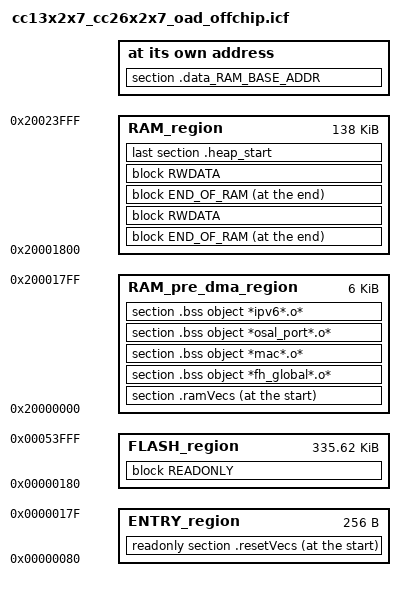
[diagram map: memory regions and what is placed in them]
/******************************************************************************

 @file  cc13x2x7_cc26x2x7_oad_offchip.icf

 @brief Linker configuration file

 Group: WCS LPC
 Target Device: cc13xx_cc26xx

 ******************************************************************************
 
 Copyright (c) 2016-2025, Texas Instruments Incorporated
 All rights reserved.

 Redistribution and use in source and binary forms, with or without
 modification, are permitted provided that the following conditions
 are met:

 *  Redistributions of source code must retain the above copyright
    notice, this list of conditions and the following disclaimer.

 *  Redistributions in binary form must reproduce the above copyright
    notice, this list of conditions and the following disclaimer in the
    documentation and/or other materials provided with the distribution.

 *  Neither the name of Texas Instruments Incorporated nor the names of
    its contributors may be used to endorse or promote products derived
    from this software without specific prior written permission.

 THIS SOFTWARE IS PROVIDED BY THE COPYRIGHT HOLDERS AND CONTRIBUTORS "AS IS"
 AND ANY EXPRESS OR IMPLIED WARRANTIES, INCLUDING, BUT NOT LIMITED TO,
 THE IMPLIED WARRANTIES OF MERCHANTABILITY AND FITNESS FOR A PARTICULAR
 PURPOSE ARE DISCLAIMED. IN NO EVENT SHALL THE COPYRIGHT OWNER OR
 CONTRIBUTORS BE LIABLE FOR ANY DIRECT, INDIRECT, INCIDENTAL, SPECIAL,
 EXEMPLARY, OR CONSEQUENTIAL DAMAGES (INCLUDING, BUT NOT LIMITED TO,
 PROCUREMENT OF SUBSTITUTE GOODS OR SERVICES; LOSS OF USE, DATA, OR PROFITS;
 OR BUSINESS INTERRUPTION) HOWEVER CAUSED AND ON ANY THEORY OF LIABILITY,
 WHETHER IN CONTRACT, STRICT LIABILITY, OR TORT (INCLUDING NEGLIGENCE OR
 OTHERWISE) ARISING IN ANY WAY OUT OF THE USE OF THIS SOFTWARE,
 EVEN IF ADVISED OF THE POSSIBILITY OF SUCH DAMAGE.

 ******************************************************************************
 
 
 *****************************************************************************/

///////////////////////////////////////////////////////////////////////////////
// Memory Sizes
///////////////////////////////////////////////////////////////////////////////
define symbol MCUBOOT_HEAD_SIZE    = 0x80;
define symbol ENTRY_SIZE           = 0x100;
define symbol MCUBOOT_RESERVED_TRAILER_SIZE = 0x2000;

define symbol PRIMARY_SLOT_BASE    = 0x0;
define symbol FLASH_BASE           = PRIMARY_SLOT_BASE + MCUBOOT_HEAD_SIZE + ENTRY_SIZE;
define symbol FLASH_SIZE           = 0x56000 - MCUBOOT_HEAD_SIZE - ENTRY_SIZE - MCUBOOT_RESERVED_TRAILER_SIZE;

define symbol ENTRY_START          = PRIMARY_SLOT_BASE + MCUBOOT_HEAD_SIZE;
define symbol ENTRY_END            = ENTRY_START + ENTRY_SIZE - 1;

define symbol RAM_BASE             = 0x20000000;
define symbol RAM_SIZE             = 0x24000;
define symbol RAM_SIZE1            = 0x1800;
define symbol RAM_BASE2            = RAM_BASE + RAM_SIZE1;
define symbol RAM_SIZE2            = RAM_SIZE - RAM_SIZE1;

define symbol NVS_BASE             = 0xA8000;
define symbol NVS_SIZE             = 0x4000;

///////////////////////////////////////////////////////////////////////////////
// Memory Definitions
///////////////////////////////////////////////////////////////////////////////

///////////////////////////////////////////////////////////////////////////////
// Flash
//
define symbol WORD_SIZE            = 4;
define symbol FLASH_MEM_ALIGN      = WORD_SIZE;

/* Define a memory region that covers the entire 4 GB addressable space */
define memory mem with size = 4G;

/* Memory Regions */
define region ENTRY_region         = mem:[from ENTRY_START to ENTRY_END];
define region FLASH_region         = mem:[from FLASH_BASE size FLASH_SIZE];

// Exported symbol for slot start address
define exported symbol __PRIMARY_SLOT_BASE = PRIMARY_SLOT_BASE;

///////////////////////////////////////////////////////////////////////////////
// RAM
//

/* Internal RAM for data used by application
 * Define two RAM regions: One before the fixed DMA region (RAM_pre_dma_region, a much smaller space),
   and one after (RAM_region, the majority of RAM).
 * This allows us to place certain RAM data sections in the pre-DMA region space.
 */
define region RAM_pre_dma_region  = mem:[from RAM_BASE size RAM_SIZE1];
define region RAM_region  = mem:[from RAM_BASE2 size RAM_SIZE2];

///////////////////////////////////////////////////////////////////////////////
// Memory Placement
///////////////////////////////////////////////////////////////////////////////

///////////////////////////////////////////////////////////////////////////////
// Memory Placement in Flash
//
// Interrupt Vector Table
place at start of ENTRY_region   { readonly section .resetVecs };
keep                             { readonly section .resetVecs };

// All other pieces of codes:
define block READONLY with alignment=WORD_SIZE{ ro };
place in FLASH_region { block READONLY };

///////////////////////////////////////////////////////////////////////////////
// Memory Placement in RAM
//

/* Place .ramVecs in start of RAM */
place at start of RAM_pre_dma_region { section .ramVecs };
do not initialize { section .ramVecs };
/* Asteriks (*) are due to differing naming convetions for compiled object files between 
    IDE, makefile, and CMake library compilation */
place in RAM_pre_dma_region { section .bss object *fh_global*.o* };
place in RAM_pre_dma_region { section .bss object *mac*.o* };
place in RAM_pre_dma_region { section .bss object *osal_port*.o* };
place in RAM_pre_dma_region { section .bss object *ipv6*.o* };

/*
 * Define CSTACK block to contain .stack section. This enables the IAR IDE
 * to properly show the stack content during debug. Place stack at end of
 * retention RAM, do not initialize (initializing the stack will destroy the
 * return address from the initialization code, causing the processor to branch
 * to zero and fault)
 */
define symbol STACKSIZE = 1600;
define block CSTACK with alignment = 8, size = STACKSIZE { section .stack };

if (isdefinedsymbol(ROM_TIMACDataAddr)) {
    place at address mem:ROM_TIMACDataAddr {section .data_RAM_BASE_ADDR };
}

/* Export stack top symbol. Used by startup file */
define exported symbol STACK_TOP = end(RAM_region) + 1;

define block RWDATA { rw };

if (isdefinedsymbol(FREERTOS)) {
    define block END_OF_RAM with fixed order {block CSTACK};
    place at end of RAM_region { block END_OF_RAM };

    place in RAM_region { block RWDATA};
}
else {
    define section .heap_start            { public heapStart: };
    define section .heap_end              { public heapEnd: };
    define block   HEAP_END with size = 1 { section .heap_end };

    define block END_OF_RAM with fixed order {
                                            block HEAP_END,
                                            block CSTACK
                                          };
    place at end of RAM_region { block END_OF_RAM };

    place in RAM_region { block RWDATA,
                   last section .heap_start};
}

initialize by copy { readwrite };
do not initialize { section .stack, section .noinit};
